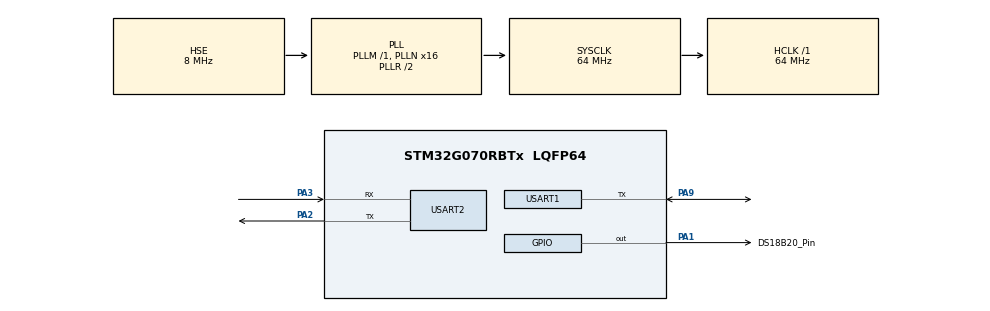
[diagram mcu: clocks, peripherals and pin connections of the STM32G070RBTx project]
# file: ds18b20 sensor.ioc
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Mcu.Family=STM32G0
Mcu.Name=STM32G070RBTx
Mcu.Package=LQFP64
PA1.GPIO_Label=DS18B20_Pin
PA1.Signal=GPIO_Output
PA2.Mode=Asynchronous
PA2.Signal=USART2_TX
PA3.Mode=Asynchronous
PA3.Signal=USART2_RX
PA9.Mode=Half_duplex(single_wire_mode)
PA9.Signal=USART1_TX
PF0-OSC_IN\ (PF0).Mode=HSE-External-Oscillator
PF0-OSC_IN\ (PF0).Signal=RCC_OSC_IN
PF1-OSC_OUT\ (PF1).Mode=HSE-External-Oscillator
PF1-OSC_OUT\ (PF1).Signal=RCC_OSC_OUT
ProjectManager.HeapSize=0x200
ProjectManager.StackSize=0x400
ProjectManager.TargetToolchain=STM32CubeIDE
RCC.ADCFreq_Value=64000000
RCC.AHBFreq_Value=64000000
RCC.CortexFreq_Value=64000000
RCC.EXTERNAL_CLOCK_VALUE=48000
RCC.HCLKFreq_Value=64000000
RCC.HSE_VALUE=8000000
RCC.HSI_VALUE=16000000
RCC.PLLN=16
RCC.PLLSourceVirtual=RCC_PLLSOURCE_HSE
RCC.SYSCLKFreq_VALUE=64000000
RCC.SYSCLKSource=RCC_SYSCLKSOURCE_PLLCLK
RCC.VCOOutputFreq_Value=128000000
TIM1.Period=0xffff-1
TIM1.Prescaler=63
USART1.VirtualMode-Half_duplex(single_wire_mode)=VM_ASYNC
USART2.VirtualMode-Asynchronous=VM_ASYNC
VP_TIM1_VS_ClockSourceINT.Mode=Internal
board=custom

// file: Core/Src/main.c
/* USER CODE BEGIN Header */
/**
  ******************************************************************************
  * @file           : main.c
  * @brief          : Main program body
  ******************************************************************************
  * @attention
  *
  * Copyright (c) 2024 STMicroelectronics.
  * All rights reserved.
  *
  * This software is licensed under terms that can be found in the LICENSE file
  * in the root directory of this software component.
  * If no LICENSE file comes with this software, it is provided AS-IS.
  *
  ******************************************************************************
  */
/* USER CODE END Header */
#include "main.h"
#include "Onewire.h"
#include "ds18b20.h"
#include <stdio.h>
#include "string.h"
/* USER CODE BEGIN Includes */

//#include "ds18b20.h"
/* USER CODE END Includes */

TIM_HandleTypeDef htim1;

UART_HandleTypeDef huart1;
UART_HandleTypeDef huart2;

/* USER CODE BEGIN PV */
float temperature;
char string[64];

/* USER CODE END PV */

void SystemClock_Config(void);
static void MX_GPIO_Init(void);
static void MX_USART1_UART_Init(void);
static void MX_USART2_UART_Init(void);
static void MX_TIM1_Init(void);

int main(void)
{

  /* MCU Configuration--------------------------------------------------------*/

  /* Reset of all peripherals, Initializes the Flash interface and the Systick. */
  HAL_Init();

  /* Configure the system clock */
  SystemClock_Config();

  /* Initialize all configured peripherals */
  MX_GPIO_Init();
  MX_USART1_UART_Init();
  MX_USART2_UART_Init();
  MX_TIM1_Init();
  /* USER CODE BEGIN 2 */
  DS18B20_Init(DS18B20_Resolution_12bits);

    HAL_UART_Transmit(&huart2, (uint8_t*)"System Initialized.\r\n", 22, HAL_MAX_DELAY);
  /* USER CODE END 2 */

  /* Infinite loop */
  while (1)
  {
	             DS18B20_ReadAll();
		         DS18B20_StartAll();
		         uint8_t ROM_tmp[8];
		         uint8_t i;

		         for (i = 0; i < DS18B20_Quantity(); i++)
		         {
		             if (DS18B20_GetTemperature(i, &temperature))
		             {
		                 DS18B20_GetROM(i, ROM_tmp);

		                 // Prepare the temperature string
		                 memset(string, 0, sizeof(string));
		                 sprintf(string, "temperature : %.2f C\r\n", i, temperature);

		                 // Send temperature data via UART
		                 HAL_UART_Transmit(&huart2, (uint8_t*)string, strlen(string), HAL_MAX_DELAY);
		             }
		         }

		         // Delay for 1 second
		         HAL_Delay(1000);
		     }
  }

void SystemClock_Config(void)
{
  RCC_OscInitTypeDef RCC_OscInitStruct = {0};
  RCC_ClkInitTypeDef RCC_ClkInitStruct = {0};

  /** Configure the main internal regulator output voltage
  */
  HAL_PWREx_ControlVoltageScaling(PWR_REGULATOR_VOLTAGE_SCALE1);

  /** Initializes the RCC Oscillators according to the specified parameters
  * in the RCC_OscInitTypeDef structure.
  */
  RCC_OscInitStruct.OscillatorType = RCC_OSCILLATORTYPE_HSE;
  RCC_OscInitStruct.HSEState = RCC_HSE_ON;
  RCC_OscInitStruct.PLL.PLLState = RCC_PLL_ON;
  RCC_OscInitStruct.PLL.PLLSource = RCC_PLLSOURCE_HSE;
  RCC_OscInitStruct.PLL.PLLM = RCC_PLLM_DIV1;
  RCC_OscInitStruct.PLL.PLLN = 16;
  RCC_OscInitStruct.PLL.PLLP = RCC_PLLP_DIV2;
  RCC_OscInitStruct.PLL.PLLR = RCC_PLLR_DIV2;
  if (HAL_RCC_OscConfig(&RCC_OscInitStruct) != HAL_OK)
  {
    Error_Handler();
  }

  /** Initializes the CPU, AHB and APB buses clocks
  */
  RCC_ClkInitStruct.ClockType = RCC_CLOCKTYPE_HCLK|RCC_CLOCKTYPE_SYSCLK
                              |RCC_CLOCKTYPE_PCLK1;
  RCC_ClkInitStruct.SYSCLKSource = RCC_SYSCLKSOURCE_PLLCLK;
  RCC_ClkInitStruct.AHBCLKDivider = RCC_SYSCLK_DIV1;
  RCC_ClkInitStruct.APB1CLKDivider = RCC_HCLK_DIV1;

  if (HAL_RCC_ClockConfig(&RCC_ClkInitStruct, FLASH_LATENCY_2) != HAL_OK)
  {
    Error_Handler();
  }
}

static void MX_TIM1_Init(void)
{

  TIM_ClockConfigTypeDef sClockSourceConfig = {0};
  TIM_MasterConfigTypeDef sMasterConfig = {0};

  htim1.Instance = TIM1;
  htim1.Init.Prescaler = 63;
  htim1.Init.CounterMode = TIM_COUNTERMODE_UP;
  htim1.Init.Period = 0xffff-1;
  htim1.Init.ClockDivision = TIM_CLOCKDIVISION_DIV1;
  htim1.Init.RepetitionCounter = 0;
  htim1.Init.AutoReloadPreload = TIM_AUTORELOAD_PRELOAD_DISABLE;
  if (HAL_TIM_Base_Init(&htim1) != HAL_OK)
  {
    Error_Handler();
  }
  sClockSourceConfig.ClockSource = TIM_CLOCKSOURCE_INTERNAL;
  if (HAL_TIM_ConfigClockSource(&htim1, &sClockSourceConfig) != HAL_OK)
  {
    Error_Handler();
  }
  sMasterConfig.MasterOutputTrigger = TIM_TRGO_RESET;
  sMasterConfig.MasterOutputTrigger2 = TIM_TRGO2_RESET;
  sMasterConfig.MasterSlaveMode = TIM_MASTERSLAVEMODE_DISABLE;
  if (HAL_TIMEx_MasterConfigSynchronization(&htim1, &sMasterConfig) != HAL_OK)
  {
    Error_Handler();
  }

}

static void MX_USART1_UART_Init(void)
{

  huart1.Instance = USART1;
  huart1.Init.BaudRate = 115200;
  huart1.Init.WordLength = UART_WORDLENGTH_8B;
  huart1.Init.StopBits = UART_STOPBITS_1;
  huart1.Init.Parity = UART_PARITY_NONE;
  huart1.Init.Mode = UART_MODE_TX_RX;
  huart1.Init.HwFlowCtl = UART_HWCONTROL_NONE;
  huart1.Init.OverSampling = UART_OVERSAMPLING_16;
  huart1.Init.OneBitSampling = UART_ONE_BIT_SAMPLE_DISABLE;
  huart1.Init.ClockPrescaler = UART_PRESCALER_DIV1;
  huart1.AdvancedInit.AdvFeatureInit = UART_ADVFEATURE_NO_INIT;
  if (HAL_HalfDuplex_Init(&huart1) != HAL_OK)
  {
    Error_Handler();
  }
  if (HAL_UARTEx_SetTxFifoThreshold(&huart1, UART_TXFIFO_THRESHOLD_1_8) != HAL_OK)
  {
    Error_Handler();
  }
  if (HAL_UARTEx_SetRxFifoThreshold(&huart1, UART_RXFIFO_THRESHOLD_1_8) != HAL_OK)
  {
    Error_Handler();
  }
  if (HAL_UARTEx_DisableFifoMode(&huart1) != HAL_OK)
  {
    Error_Handler();
  }

}

static void MX_USART2_UART_Init(void)
{

  huart2.Instance = USART2;
  huart2.Init.BaudRate = 115200;
  huart2.Init.WordLength = UART_WORDLENGTH_8B;
  huart2.Init.StopBits = UART_STOPBITS_1;
  huart2.Init.Parity = UART_PARITY_NONE;
  huart2.Init.Mode = UART_MODE_TX_RX;
  huart2.Init.HwFlowCtl = UART_HWCONTROL_NONE;
  huart2.Init.OverSampling = UART_OVERSAMPLING_16;
  huart2.Init.OneBitSampling = UART_ONE_BIT_SAMPLE_DISABLE;
  huart2.Init.ClockPrescaler = UART_PRESCALER_DIV1;
  huart2.AdvancedInit.AdvFeatureInit = UART_ADVFEATURE_NO_INIT;
  if (HAL_UART_Init(&huart2) != HAL_OK)
  {
    Error_Handler();
  }
  if (HAL_UARTEx_SetTxFifoThreshold(&huart2, UART_TXFIFO_THRESHOLD_1_8) != HAL_OK)
  {
    Error_Handler();
  }
  if (HAL_UARTEx_SetRxFifoThreshold(&huart2, UART_RXFIFO_THRESHOLD_1_8) != HAL_OK)
  {
    Error_Handler();
  }
  if (HAL_UARTEx_DisableFifoMode(&huart2) != HAL_OK)
  {
    Error_Handler();
  }

}

static void MX_GPIO_Init(void)
{
  GPIO_InitTypeDef GPIO_InitStruct = {0};

  /* GPIO Ports Clock Enable */
  __HAL_RCC_GPIOF_CLK_ENABLE();
  __HAL_RCC_GPIOA_CLK_ENABLE();

  /*Configure GPIO pin Output Level */
  HAL_GPIO_WritePin(DS18B20_Pin_GPIO_Port, DS18B20_Pin_Pin, GPIO_PIN_RESET);

  /*Configure GPIO pin : DS18B20_Pin_Pin */
  GPIO_InitStruct.Pin = DS18B20_Pin_Pin;
  GPIO_InitStruct.Mode = GPIO_MODE_OUTPUT_PP;
  GPIO_InitStruct.Pull = GPIO_NOPULL;
  GPIO_InitStruct.Speed = GPIO_SPEED_FREQ_LOW;
  HAL_GPIO_Init(DS18B20_Pin_GPIO_Port, &GPIO_InitStruct);

}

void Error_Handler(void)
{
  __disable_irq();
  while (1)
  {
  }
}
